# McASP_DSP register map
Vendor: Texas Instruments
Peripheral module from a debugger description file (folder omap4430).
Registers are 32-bit, read-write, reset 0x0 unless marked. A register's access mark holds for its fields unless they carry their own. Offsets are as the file gives them; lines under a group give offsets from that group; [hi:lo] are bit positions; {n}, {i} and the like mark numbered series; 'fields as' and 'values as' point back to an identical list; <NAME> marks a mode.

## McASP_DSP
0x00 MCASP_PID ro reset not defined — Peripheral identification register
  [31:0] REVISION — IP revision
0x04 MCASP_SYSCONFIG access per field reset 0x2 — Power idle module configuration register.
  [1:0] IDLE_MODE rw — 0x0: Force-idle mode 0x1: No-idle mode 0x2: Smart-idle mode - default state 0x3: Reserved
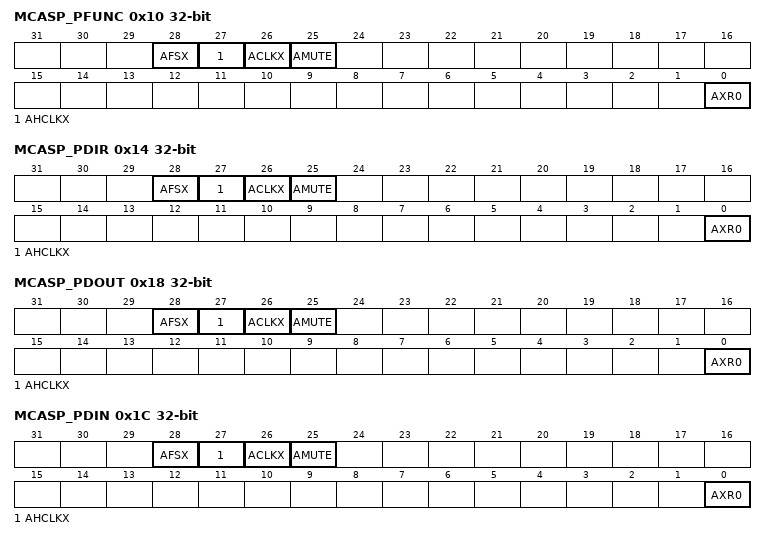
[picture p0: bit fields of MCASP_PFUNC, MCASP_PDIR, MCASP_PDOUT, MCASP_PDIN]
0x10 MCASP_PFUNC — Specifies the function of the pins as either a McASP pin or a GPIO pin
  [all] fields
    0=Pin functions as McASP pin; 1=Pin functions as GIO pin
  [28] AFSX — Determines if abe_mcasp_afsx pin functions as McASP or GPIO.
  [27] AHCLKX — Determines if abe_mcasp_ahclkx pin functions as McASP or GPIO.
  [26] ACLKX — Determines if abe_mcasp_aclkx pin functions as McASP or GPIO.
  [25] AMUTE — Determines if abe_mcasp_amute pin functions as McASP or GPIO.
  [0] AXR0 — Determines if abe_mcasp_axr pin functions as McASP or GPIO.
0x14 MCASP_PDIR — Pin direction register - specifies the direction of the McASP pins as either an input or an output pin. For the module to operate properly, configure them as outputs.
  [all] fields
    0=Input; 1=Output
  [28] AFSX — Determines if abe_mcasp_afsx pin functions as an input or output.
  [27] AHCLKX — Determines if abe_mcasp_ahclkx pin functions as an input or output.
  [26] ACLKX — Determines if abe_mcasp_aclkx pin functions as an input or output.
  [25] AMUTE — Determines if abe_mcasp_amute pin functions as an input or output.
  [0] AXR0 — Determines if abe_mcasp_axr pin functions as an input or output.
0x18 MCASP_PDOUT — Pin data output register - holds a value for data out at all times, and may be read back at all times. The value held by is not affected by writing to and . However, the data value in is driven out onto the McASP pin only if the corresponding bit in is set to 1 (GPIO function) and the corresponding bit in is set to 1 (output).
  [all] fields
    0=The pin drives low; 1=The pin drives high
  [28] AFSX — Determines drive on AFSX output pin when the correspondingMCASP_PFUNC[28] and MCASP_PDIR[28] bits are set to 1.
  [27] AHCLKX — Determines drive on AHCLKX output pin when the correspondingMCASP_PFUNC[27] and MCASP_PDIR[27] bits are set to 1.
  [26] ACLKX — Determines drive on ACLKX output pin when the correspondingMCASP_PFUNC[26] and MCASP_PDIR[26] bits are set to 1
  [25] AMUTE — Determines drive on AMUTE output pin when the correspondingMCASP_PFUNC[25] and MCASP_PDIR[25] bits are set to 1.
  [0] AXR0 — Determines drive on abe_mcasp_axr output pin when the correspondingMCASP_PFUNC[0] and MCASP_PDIR[0] bits are set to 1.
0x1C MCASP_PDIN ro — Pin data input register - holds the state of all the McASP pins. allows reading the actual value of the pin, regardless of the state of and .
  [all] fields
    0=Pin is logic low; 1=Pin is logic high
  [28] AFSX — Logic level on abe_mcasp_afsx pin.
  [27] AHCLKX — Logic level on abe_mcasp_ahclkx pin.
  [26] ACLKX — Logic level on abe_mcasp_aclkx pin.
  [25] AMUTE — Logic level on abe_mcasp_amute pin.
  [0] AXR0 — Logic level on abe_mcasp_axr pin.
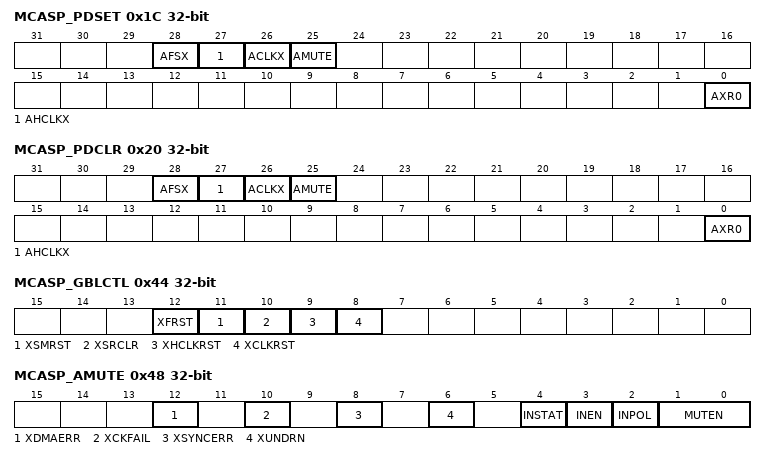
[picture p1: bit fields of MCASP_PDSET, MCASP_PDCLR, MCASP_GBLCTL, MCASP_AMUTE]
0x1C MCASP_PDSET wo — The pin data set register is an alias of the pin data output register () for writes only. Writing a 1 to the bit sets the corresponding bit in and, if = 1 (GPIO function) and = 1 (output), drives a logic high on the pin.
  [28] AFSX — Allows the corresponding AFSX bit inMCASP_PDOUT to be set to a logic high without affecting other I/O pins controlled by the same port.
    0=No effect; 1=[28] bit is set to 1
  [27] AHCLKX — Allows the corresponding AHCLKX bit inMCASP_PDOUT to be set to a logic high without affecting other I/O pins controlled by the same port.
    0=No effect; 1=[27] bit is set to 1
  [26] ACLKX — Allows the corresponding ACLKX bit inMCASP_PDOUT to be set to a logic high without affecting other I/O pins controlled by the same port.
    0=No effect; 1=[26] bit is set to 1
  [25] AMUTE — Allows the corresponding AMUTE bit inMCASP_PDOUT to be set to a logic high without affecting other I/O pins controlled by the same port.
    0=No effect; 1=[25] bit is set to 1
  [0] AXR0 — Allows the AXR0 bit inMCASP_PDOUT to be set to a logic high without affecting other I/O pins controlled by the same port.
    0=No effect; 1=[0] bit is set to 1
0x20 MCASP_PDCLR — The pin data clear register is an alias of the pin data output register () for writes only. Writing a 1 to the bit clears the corresponding bit in and, if = 1 (GPIO function) and = 1 (output), drives a logic low on the pin.
  [28] AFSX — Allows the corresponding AFSX bit inMCASP_PDOUT to be cleared to a logic low without affecting other I/O pins controlled by the same port.
    0=No effect; 1=[28] bit is cleared to 0
  [27] AHCLKX — Allows the corresponding AHCLKX bit inMCASP_PDOUT to be cleared to a logic low without affecting other I/O pins controlled by the same port.
    0=No effect; 1=[27] bit is cleared to 0
  [26] ACLKX — Allows the corresponding ACLKX bit inMCASP_PDOUT to be cleared to a logic low without affecting other I/O pins controlled by the same port.
    0=No effect; 1=[26] bit is cleared to 0
  [25] AMUTE — Allows the corresponding AMUTE bit inMCASP_PDOUT to be cleared to a logic low without affecting other I/O pins controlled by the same port.
    0=No effect; 1=[25] bit is cleared to 0
  [0] AXR0 — Allows the AXR0 bit inMCASP_PDOUT to be cleared to a logic low without affecting other I/O pins controlled by the same port.
    0=No effect; 1=[0] bit is cleared to 0
0x44 MCASP_GBLCTL — Global transmit control register - provides initialization of the transmit section. The bit fields in are synchronized and latched by the abe_mcasp_aclkx clock. Before programming , ensure that the serial clocks are running. If the corresponding external serial clock, abe_mcasp_clkx, is not yet running, select the internal serial clock source in AHCLKXCTL and ACLKXCTL before programming . Also, after programming any bits in , do not proceed until reading back from and verifying that the bits in are latched.
  [12] XFRST — Transmit frame-sync generator reset enable bit
    0=The transmit frame-sync generator is reset; 1=The transmit frame-sync generator is active. When released from reset, the transmit frame-sync generator begins counting serial clocks and generating frame sync as programmed.
  [11] XSMRST — Transmit state-machine reset enable bitabe_mcasp_axr pin state: If[0] = 0 and [0] = 1, the serializer drives the abe_mcasp_axr pin to the state specified for inactive time slot .
    0=The transmit state-machine is held in reset; 1=The transmit state-machine is released from reset. When released from reset, the transmit state-machine immediately transfers data from XBUF[n] to XRSR[n]. The transmit state-machine sets the underrun flag (XUNDRN) in MCASP_TXSTAT, if XBUF[n] have not been preloaded with data before reset is released. The transmit state-machine also immediately begins detecting frame sync and is ready to transmit. Transmission of TDM time slot begins at slot 0 after reset is released.
  [10] XSRCLR — Transmit serializer clear enable bit. By clearing and then setting this bit, the transmit buffer is flushed to an empty state (XDATA = 1). If XSMRST = 1, XSRCLR = 1, XDATA = 1, and XBUF is not loaded with new data before the start of the next active time slot, an underrun occurs.
    0=The transmit serializer is cleared; 1=The transmit serializer is active. When the transmit serializer is first taken out of reset (XSRCLR changes from 0 to 1), the transmit data ready bit (XDATA) in MCASP_TXSTAT is set to indicate XBUF is ready to be written.
  [9] XHCLKRST — Transmit high-frequency clock divider reset enable bit
    0=The transmitter high-frequency clock divider is held in reset; 1=The transmitter high-frequency clock divider is running
  [8] XCLKRST — Transmit clock divider reset enable bit
    0=The transmit clock divider is held in reset. When the clock divider is in reset, it passes through a divide-by-1 of its input.; 1=The transmit clock divider is running
0x48 MCASP_AMUTE access per field — Mute control register - Controls the McASP mute output pin (abe_mcasp_amute)
  [12] XDMAERR rw — Drives AMUTE active enable bit on transmit DMA error (XDMAERR).
    0=Drive is disabled. Detection of transmit DMA error is ignored by abe_mcasp_amute.; 1=Drive is enabled (active). Upon detection of transmit DMA error, abe_mcasp_amute is active and is driven according to MUTEN bits.
  [10] XCKFAIL rw — XMT bad clock. Drives AMUTE active enable bit on transmit clock failure (XCKFAIL).
    0=Drive is disabled. Detection of transmit clock failure is ignored by abe_mcasp_amute.; 1=Drive is enabled (active). Upon detection of transmit clock failure, abe_mcasp_amute is active and is driven according to MUTEN bits.
  [8] XSYNCERR rw — XMT unexpected FS. Drives AMUTE active enable bit on unexpected transmit frame-sync error (XSYNCERR).
    0=Drive is disabled. Detection of unexpected transmit frame-sync error is ignored by abe_mcasp_amute.; 1=Drive is enabled (active). Upon detection of unexpected transmit frame-sync error, abe_mcasp_amute is active and is driven according to MUTEN bit.
  [6] XUNDRN rw — XMT underrun occurs. Drives AMUTE active enable bit on ransmit underrun error (XUNDRN).
    0=Drive is disabled. Detection of transmit underrun error is ignored by abe_mcasp_amute.; 1=Drive is enabled (active). Upon detection of transmit underrun error, abe_mcasp_amute is active and is driven according to MUTEN bit.
  [4] INSTAT ro — Status of mute in pin, determines drive on abe_mcasp_axr pin when theMCASP_PFUNC[0] and MCASP_PDIR[0] bits are set to 1.
    0=INSTAT_0_r (Inactive); 1=INSTAT_1_r (Active. Audio mute in error is detected.)
  [3] INEN rw — Drive abe_mcasp_amute active when abe_mcasp_amutein error is active.
    0=Drive is disabled. abe_mcasp_amutein is ignored by abe_mcasp_amute.; 1=Drive is enabled (active). INSTAT = 1 drives abe_mcasp_amute active.
  [2] INPOL rw — Audio mute in (abe_mcasp_amutein) polarity select bit
    0=Polarity is active high. A high on abe_mcasp_amutein sets INSTAT to 1.; 1=Polarity is active low. A low on abe_mcasp_amutein sets INSTAT to 1.
  [1:0] MUTEN rw — abe_mcasp_amute pin enable bit field (unless overridden by GPIO registers)
    0=Disabled, pin goes to 3-state condition; 1=Pin is driven high if error is detected; 2=Pin is driven low if error is detected
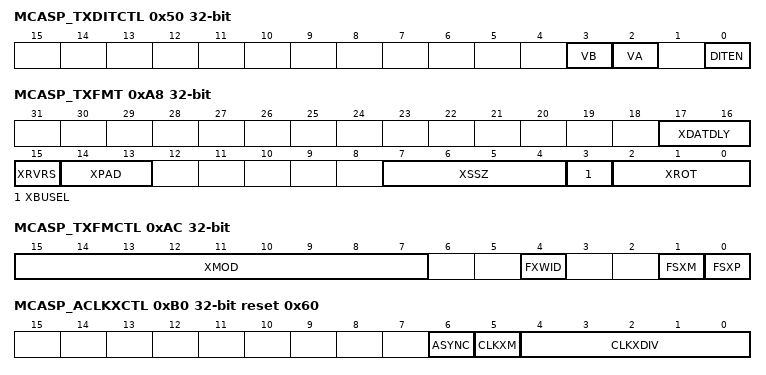
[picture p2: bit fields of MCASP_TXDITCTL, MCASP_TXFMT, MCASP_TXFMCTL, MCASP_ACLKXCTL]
0x50 MCASP_TXDITCTL — Transmit DIT mode control register, controls DIT operations of the McASP
  [3] VB — Valid bit for odd time slots (DIT right subframe).
    0=V bit is 0 during odd DIT subframes; 1=V bit is 1 during odd DIT subframes
  [2] VA — Valid bit for even time slots (DIT left subframe).
    0=V bit is 0 during even DIT subframes; 1=V bit is 1 during even DIT subframes
  [0] DITEN — DIT mode enable bit
    0=DIT mode is disabled; 1=DIT mode is enabled. Transmitter operates in DIT encoded mode.
0xA4 MCASP_TXMASK — Transmit format unit bit mask register - Determines which bits of the transmitted data are masked off before being shifted out the McASP
  [31:0] XMASK_31_to_0 — Transmit data mask enable bit
    0=The corresponding bit of transmit data is masked out and then transmitted out the McASP in place of the original bit; 1=The corresponding bit of transmit data is transmitted out the McASP
0xA8 MCASP_TXFMT — Transmit bitstream format register - configures the transmit data format
  [17:16] XDATDLY — Transmit sync bit delay
    0=0 bit delay - The first transmit data bit, abe_mcasp_axr, occurs in the same abe_mcasp_aclkx cycle as the transmit frame sync (abe_mcasp_afsx)
  [15] XRVRS — Transmit serial bitstream order 0x0: Bitstream is LSB first. No bit reversal is performed in transmit format unit. 0x1: Reserved
  [14:13] XPAD — Pad value for extra bits in slot not belonging to word defined by XMASK. This field only applies to bits when XMASK[n] = 0. 0x0: Pad extra bits with 0. 0x1 to 0x3: Reserved
  [7:4] XSSZ — Transmit slot size0x0 to 0xE: Reserved .
    15=Slot size is 32 bits
  [3] XBUSEL — Selects whether writes to the serializer buffer XBUF originate from the peripheral configuration port or the DMA port.
    0=Writes to XBUF originate from the data port. Writes to XBUF from the peripheral configuration port are ignored with no effect on the McASP.; 1=Writes to XBUF originate from the peripheral configuration port. Writes to XBUF from the data port are ignored with no effect on the McASP.
  [2:0] XROT — Right-rotation value for transmit rotate right format unit
    0=Rotate right by 0 (no rotation); 1=Rotate right by 4 bit positions; 2=Rotate right by 8 bit positions; 3=Rotate right by 12 bit positions; 4=Rotate right by 16 bit positions; 5=Rotate right by 20 bit positions; 6=Rotate right by 24 bit positions; 7=Rotate right by 28 bit positions
0xAC MCASP_TXFMCTL — Transmit frame-sync control register - configures the transmit frame sync (abe_mcasp_afsx).
  [15:7] XMOD — Transmit frame-sync mode select bits 0x180: 384-slot DIT mode All other: Reserved
  [4] FXWID — The transmit frame-sync width select bit indicates the width of the transmit frame sync (abe_mcasp_afsx) during its active period.
    0=Single bit
  [1] FSXM — Transmit frame-sync generation select bit
    1=Internally-generated transmit frame sync
  [0] FSXP — Transmit frame-sync polarity select bit
    0=Rising Edge - A rising edge on transmit frame sync (abe_mcasp_afsx) indicates the beginning of a frame
0xB0 MCASP_ACLKXCTL reset 0x60 — Transmit clock control register - Configures the transmit bit clock (abe_mcasp_aclkx) and the transmit clock generator.
  [6] ASYNC — Transmit operation asynchronous enable bit
    1=Asynchronous
  [5] CLKXM — Transmit bit clock source bit
    1=Internal (output of divider)
  [4:0] CLKXDIV — Transmit bit clock divide ratio bits, determine the divide-down ratio from AHCLKX to ACLKX. 0x0: Divide-by-1 0x1: Divide-by-2 0x2 to 0x1F: Divide-by-3 to divide-by-32
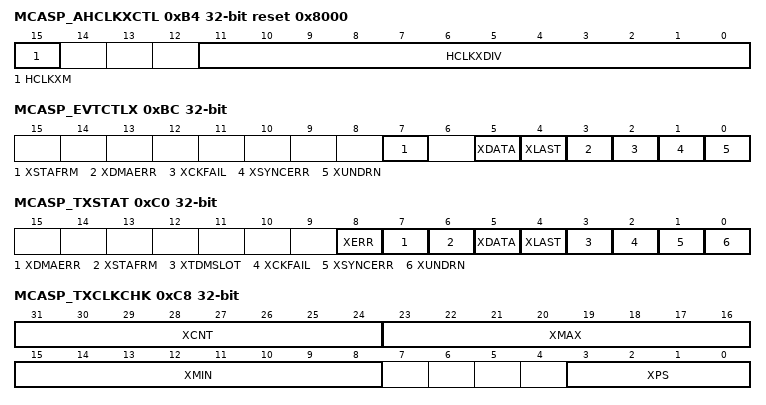
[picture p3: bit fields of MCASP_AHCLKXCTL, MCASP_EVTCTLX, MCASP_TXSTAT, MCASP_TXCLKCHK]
0xB4 MCASP_AHCLKXCTL reset 0x8000 — High-frequency transmit clock control register - Configures the transmit high-frequency master clock (abe_mcasp_ahclkx) and the transmit clock generator.
  [15] HCLKXM — Transmit high-frequency clock source bit
    1=Internal transmit high-frequency clock source from output of programmable high clock divider
  [11:0] HCLKXDIV — Transmit high-frequency clock divide ratio bits determine the divide-down ratio from AUXCLK to abe_mcasp_ahclkx. 0x0: Divide-by-1 0x1: Divide-by-2 0x2 to 0xFFF: Divide-by-3 to divide-by-4096
0xB8 MCASP_TXTDM — Transmit TDM slot 0-31 register - TDM time slot counter range is to 384 slots (to support SPDIF blocks of 384 subframes).
  [31:0] XTDMS_31_to_0 — Transmitter mode during TDM time slot n
    1=The transmit TDM time slot n is active. The transmit serializer shifts out data during this slot according to the serializer control register (MCASP_SRCTL).
0xBC MCASP_EVTCTLX — Transmitter Interrupt control register - controls generation of the McASP transmit interrupt (XINT). When the register bit(s) is set to 1, the occurrence of the enabled McASP condition(s) generates XINT.
  [7] XSTAFRM — Transmit start of frame interrupt enable bit
    0=Interrupt is disabled. A transmit-start-of-frame interrupt does not generate a McASP transmit interrupt (XINT).; 1=Interrupt is enabled. A transmit-start-of-frame interrupt generates a McASP transmit interrupt (XINT).
  [5] XDATA — Transmit data-ready interrupt enable bit
    0=Interrupt is disabled. A transmit data-ready interrupt does not generate a McASP transmit interrupt (XINT).; 1=Interrupt is enabled. A transmit data-ready interrupt generates a McASP transmit interrupt (XINT).
  [4] XLAST — Transmit last slot interrupt enable bit
    0=Interrupt is disabled. A transmit-last-slot interrupt does not generate a McASP transmit interrupt (XINT).; 1=Interrupt is enabled. A transmit-last-slot interrupt generates a McASP transmit interrupt (XINT).
  [3] XDMAERR — Transmit DMA error interrupt enable bit
    0=Interrupt is disabled. A transmit DMA error interrupt does not generate a McASP transmit interrupt (XINT).; 1=Interrupt is enabled. A transmit DMA error interrupt generates a McASP transmit interrupt (XINT).
  [2] XCKFAIL — Transmit clock failure interrupt enable bit
    0=Interrupt is disabled. A transmit clock failure interrupt does not generate a McASP transmit interrupt (XINT).; 1=Interrupt is enabled. A transmit clock failure interrupt generates a McASP transmit interrupt (XINT).
  [1] XSYNCERR — Unexpected transmit frame-sync interrupt enable bit
    0=Interrupt is disabled. An unexpected transmit frame-sync interrupt does not generate a McASP transmit interrupt (XINT).; 1=Interrupt is enabled. An unexpected transmit frame-sync interrupt generates a McASP transmit interrupt (XINT).
  [0] XUNDRN — Transmitter underrun interrupt enable bit
    0=Interrupt is disabled. A transmitter underrun interrupt does not generate a McASP transmit interrupt (XINT).; 1=Interrupt is enabled. A transmitter underrun interrupt generates a McASP transmit interrupt (XINT).
0xC0 MCASP_TXSTAT access per field — Transmitter status register - If the McASP logic attempts to set an interrupt flag in the same cycle that the CPU writes to the flag to clear it, the McASP logic has priority and the flag remains set. This also causes the generation of a new interrupt request.
  [8] XERR rw — XERR bit always returns a logic-OR of: XUNDRN | XSYNCERR | XCKFAIL | XDMAERR. Allows a single bit to be checked to determine if a transmitter error interrupt has occurred.
    0=No errors have occurred; 1=An error has occurred
  [7] XDMAERR rw — Transmit DMA error flag. XDMAERR is set when the CPU or DMA writes more words to the data port of the McASPin a given time slot than it should. Causes a transmit interrupt (XINT) if this bit and XDMAERR inMCASP_EVTCTLX are set. This bit is cleared by writing a 1 to it. Writing a 0 has no effect.
    0=Transmit DMA error did not occur; 1=Transmit DMA error occurred
  [6] XSTAFRM rw — Transmit start of frame flag. Causes a transmit interrupt (XINT) if this bit and XSTAFRM inMCASP_EVTCTLX are set. This bit is cleared by writing a 1 to it. Writing a 0 has no effect.
    0=No new transmit frame sync (AFSX) is detected; 1=A new transmit frame sync (AFSX) is detected
  [5] XDATA rw — Transmit data ready flag. Causes a transmit interrupt (XINT) if this bit and XDATA inMCASP_EVTCTLX are set. This bit is cleared by writing a 1 to iit. Writing a 0 has no effect
    0=XBUF is written and is full; 1=Data is copied from XBUF to XRSR. XBUF is empty and ready to be written. XDATA is also set when the transmit serializers are taken out of reset. When XDATA is set, it always causes a DMA event (AXEVT).
  [4] XLAST rw — Transmit last slot flag. XLAST, along with XDATA, are set if the current slot is the last slot in a frame. Causes a transmit interrupt (XINT) if this bit and XLAST inMCASP_EVTCTLX are set. This bit is cleared by writing a 1 to iit. Writing a 0 has no effect.
    0=Current slot is not the last slot in a frame; 1=Current slot is the last slot in a frame. XDATA is also set.
  [3] XTDMSLOT ro — Returns the LSB of XSLOT. Allows a single read of XSTAT to determine whether the current TDM time slot is even or odd.
    0=XTDMSLOT_0_r (Current TDM time slot is odd.); 1=XTDMSLOT_1_r (Current TDM time slot is even.)
  [2] XCKFAIL rw — Transmit clock failure flag. XCKFAIL is set when the transmit clock failure detection circuit reports an error. Causes a transmit interrupt (XINT) if this bit and XCKFAIL inMCASP_EVTCTLX are set. This bit is cleared by writing a 1 to iit. Writing a 0 has no effect.
    0=Transmit clock failure did not occur; 1=Transmit clock failure occurred
  [1] XSYNCERR rw — Unexpected transmit frame-sync flag. XSYNCERR is set when a new transmit frame sync (AFSX) occurs before it is expected. Causes a transmit interrupt (XINT) if this bit and XSYNCERR inMCASP_EVTCTLX are set. This bit is cleared by writing a 1 to iit. Writing a 0 has no effect.
    0=Unexpected transmit frame sync did not occur; 1=Unexpected transmit frame sync occurred
  [0] XUNDRN rw — Transmitter underrun flag. XUNDRN is set when the transmit serializer is instructed to transfer data from XBUF to XRSR, but XBUF has not yet been serviced with new data since the last transfer. Causes a transmit interrupt (XINT) if this bit and XUNDRN inMCASP_EVTCTLX are set. This bit is cleared by writing a 1 to iit. Writing a 0 has no effect.
    0=Transmitter underrun did not occur; 1=Transmitter underrun occurred
0xC4 MCASP_TXTDMSLOT ro — Current transmit TDM time slot register
  [9:0] XSLOTCNT — Current transmit time slot count. the value of this register is 0b0101111111 (0x17f) during reset and 0 after reset.
0xC8 MCASP_TXCLKCHK access per field — Transmit clock check control register - configures the transmit clock failure detection circuit.
  [31:24] XCNT ro — Transmit clock count value (from previous measurement). The clock circuit continually counts the number of system clocks for every 32 transmit high-frequency master clock (abe_mcasp_ahclkx) signals, and stores the count in XCNT until the next measurement is taken
  [23:16] XMAX rw — 0x0 to 0xFF: Transmit clock maximum boundary. This 8-bit unsigned value sets the maximum allowed boundary for the clock check counter after 32 transmit high-frequency master clock (abe_mcasp_ahclkx) signals have been received. If the current counter value is greater than XMAX after counting 32 AHCLKX signals, XCKFAIL in XSTAT is set. The comparison is performed using unsigned arithmetic.
  [15:8] XMIN rw — 0x0 to 0xFF: Transmit clock minimum boundary. This 8-bit unsigned value sets the minimum allowed boundary for the clock check counter after 32 transmit high-frequency master clock (abe_mcasp_ahclkx) signals have been received. If XCNT is less than XMIN after counting 32 AHCLKX signals, XCKFAIL in XSTAT is set. The comparison is performed using unsigned arithmetic.
  [3:0] XPS rw — Transmit clock check prescaler value 0x0: McASP system clock divided by 1 0x1: McASP system clock divided by 2 0x2: McASP system clock divided by 4 0x3: McASP system clock divided by 8 0x4: McASP system clock divided by 16 0x5: McASP system clock divided by 32 0x6: McASP system clock divided by 64 0x7: McASP system clock divided by 128 0x8: McASP system clock divided by 256 0x9 to 0xF: Reserved
0xCC MCASP_TXEVTCTL — Transmitter DMA event control register
  [0] XDATDMA — Transmit data DMA request enable bit. When writing to this field, always write the default value of 0.
    0=The transmit data DMA request is enabled; 1=The transmit data DMA request is disabled
{0x100+4i} MCASP_DITCSRAi_{i} (i=0..5) — DIT left channel status register - All six 32-bit registers (I = 0 to 5) can store 192 bits of channel status data for a complete block of transmission. The DIT reuses the same data for the next block. Make sure to update the register file before a different set of data needs to be sent.
  [31:0] DITCSRAi — Left (even TDM slot ) channel status
{0x118+4i} MCASP_DITCSRBi_{i} (i=0..5) — DIT right channel status register - All six 32-bit registers (I = 0 to 5) can store 192 bits of channel status data for a complete block of transmission. The DIT reuses the same data for the next block. Make sure to update the register file before a different set of data needs to be sent.
  [31:0] DITCSRBi — Right (odd TDM slot ) channel status
{0x130+4i} MCASP_DITUDRAi_{i} (i=0..5) — DIT left channel user data register - provides the user data of each left channel (even TDM time slot). All six 32-bit registers (I = 0 to 5) can store 192 bits of user data for a complete block of transmission. The DIT reuses the same data for the next block. Make sure to update the register before a different set of data needs to be sent.
  [31:0] DITUDRAi — Left (even TDM slot ) user data
{0x148+4i} MCASP_DITUDRBi_{i} (i=0..5) — DIT right user data register - provides the user data of each right channel (odd TDM time slot). All six 32-bit registers (I = 0 to 5) can store 192 bits of user data for a complete block of transmission. The DIT reuses the same data for the next block. Make sure to update the register before a different set of data needs to be sent.
  [31:0] DITUDRBi — Right (odd TDM slot ) user data
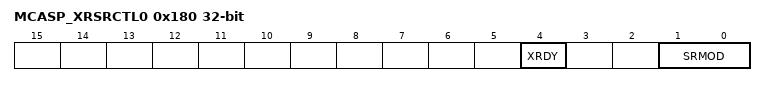
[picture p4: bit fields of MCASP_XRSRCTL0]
0x180 MCASP_XRSRCTL0 access per field — Serializer control register
  [4] XRDY ro — Transmit buffer ready bit
    0=XRDY_0_r (The transmit buffer () contains data.); 1=XRDY_1_r (The transmit buffer () is empty and needs to be written before the start of the next time slot or a transmit underrun occurs.)
  [1:0] SRMOD rw — Serializer mode bit
    0=The serializer is inactive; 1=The serializer is operating in transmit mode. 0x2: Reserved 0x3: Reserved
0x200 MCASP_TXBUF0 — Transmit buffer - The transmit buffer for the serializer holds data from the transmit format unit.
  [31:0] XBUF0 — Transmit buffer
